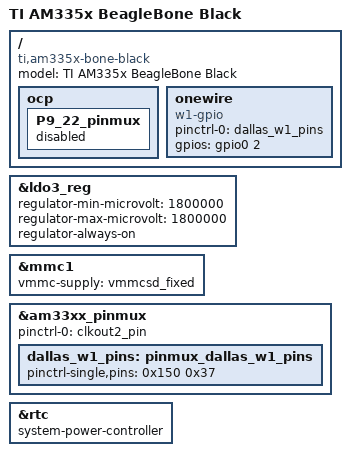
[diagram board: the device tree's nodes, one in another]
/*
 * Copyright (C) 2012 Texas Instruments Incorporated - http://www.ti.com/
 *
 * This program is free software; you can redistribute it and/or modify
 * it under the terms of the GNU General Public License version 2 as
 * published by the Free Software Foundation.
 */

/dts-v1/;

#include "am33xx.dtsi"
#include "am335x-bone-common-no-capemgr.dtsi"

/ {
        model = "TI AM335x BeagleBone Black";
        compatible = "ti,am335x-bone-black", "ti,am335x-bone", "ti,am33xx";
};

//#include "am335x-boneblack-1ghz.dtsi"

&ldo3_reg {
        regulator-min-microvolt = <1800000>;
        regulator-max-microvolt = <1800000>;
        regulator-always-on;
};

&mmc1 {
        vmmc-supply = <&vmmcsd_fixed>;
};

&am33xx_pinmux {
        pinctrl-names = "default";
        pinctrl-0 = <&clkout2_pin>;
};

#include "am335x-peripheral-emmc.dtsi"
#include "am335x-bone-pinmux-emmc.dtsi"

&rtc {
        system-power-controller;
};

/* 1-WIRE YEA BOY */

/ {
        ocp {
                P9_22_pinmux {status = "disabled"; }; /* Dallas 1W */
        };
};

/ {
        onewire {
                compatible      = "w1-gpio";
                pinctrl-names   = "default";
                pinctrl-0       = <&dallas_w1_pins>;
                status          = "okay";
                gpios           = <&gpio0 2 0>;
        };
};

&am33xx_pinmux {
        dallas_w1_pins: pinmux_dallas_w1_pins {
                pinctrl-single,pins = <0x150 0x37>;
        };
};
